# MC3_MMR_ICONT register map
Vendor: Texas Instruments
Peripheral module from a debugger description file (folder DRA75x_DRA74x).
Registers are 32-bit, read-write, reset 0x0 unless marked. A register's access mark holds for its fields unless they carry their own. Offsets are as the file gives them; lines under a group give offsets from that group; [hi:lo] are bit positions; {n}, {i} and the like mark numbered series; 'fields as' and 'values as' point back to an identical list; <NAME> marks a mode.

## MC3_MMR_ICONT
0x00 MC_PID ro reset not defined — PID register
  [31:0] PID — PID of the MC3 module
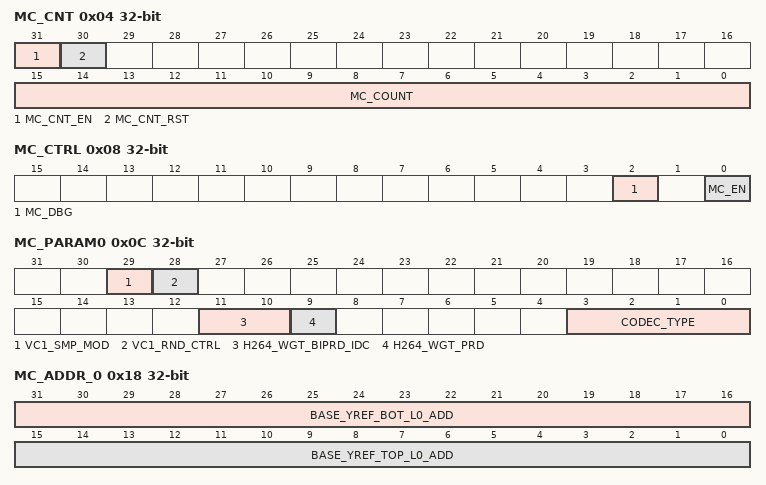
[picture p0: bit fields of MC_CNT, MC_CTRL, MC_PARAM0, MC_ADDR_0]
0x04 MC_CNT access per field — Benchmark counter register
  [31] MC_CNT_EN rw — Counter enable (MC_CNT_EN) 0: The benchmark counter is disabled. 1: The benchmark counter is enabled.
  [30] MC_CNT_RST wo — Counter reset (MC_CNT_RST) Writing 0 results in no effect. Writing 1 results in clearing the benchmark counter to 0. Always read as 0.
  [15:0] MC_COUNT ro — Counter value (MC_COUNT). Indicates current value of the benchmark counter. When MC_CNT_EN is 1 and IP is busy (en = 1), the benchmark counter counts up based on clk_mc. Writing has no effect.
0x08 MC_CTRL access per field — Control register
  [2] MC_DBG rw — H.264 MBAFF debug mode bit (MC_DBG). This bit is used for H.264 MBAFF mode only. For the other codecs, this bit must be 0. 0: Normal mode 1: Debug mode(1MB prediction/step)
  [0] MC_EN rw — Module start and status (MC_EN). Writing 1 starts a set of commands, and writing 0 is ignored. Writing to this register is forbidden while MC_EN = 1. 0: Idle 1: Busy
0x0C MC_PARAM0 access per field — Motion compression parameter register
  [29] VC1_SMP_MOD rw — VC-1 sample mode 0: Bilinear Interpolation 1: Bicubic Interpolation
  [28] VC1_RND_CTRL rw — VC-1 round control bit
  [11:10] H264_WGT_BIPRD_IDC rw — H.264 weighted_bipred_idc
  [9] H264_WGT_PRD rw — H.264 weighted_pred_flag
  [3:0] CODEC_TYPE rw — Codec_type select 0: H.264 2: VC-1 4: MPEG-4 5: MPEG-2 6: AVS-1.0 8: RealVideo-8/9/10 9: On2 VP6 10: On2 VP7
0x10 MC_PARAM1 ro — Motion compression parameter register
0x18 MC_ADDR_0 — Base address of reference data Luma L0
  [31:16] BASE_YREF_BOT_L0_ADD — Base address of reference data Y L0 bottom (BASE_YREF_BOT_L0_ADD) (Reference for bottom field)
  [15:0] BASE_YREF_TOP_L0_ADD — Base address of reference data Y L0 top (BASE_YREF_TOP_L0_ADD) (Reference for progressive/top field)
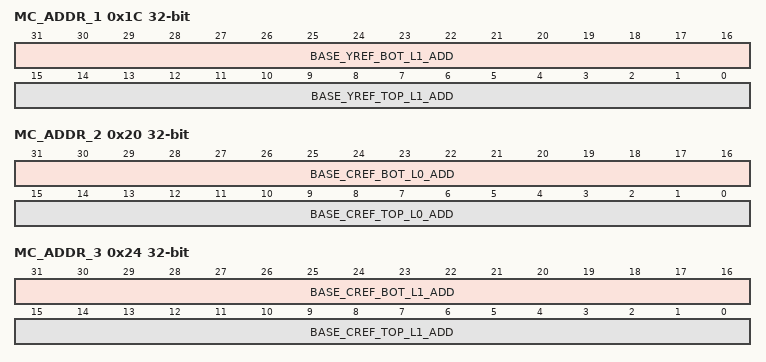
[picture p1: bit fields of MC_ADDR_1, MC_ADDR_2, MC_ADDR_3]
0x1C MC_ADDR_1 — Base address of reference data Luma L1
  [31:16] BASE_YREF_BOT_L1_ADD — Base address of reference data Y L1 bottom (BASE_YREF_BOT_L1_ADD) (Reference for bottom field)
  [15:0] BASE_YREF_TOP_L1_ADD — Base address of reference data Y L1 top (BASE_YREF_TOP_L1_ADD) (Reference for progressive/top field)
0x20 MC_ADDR_2 — Base address of reference data chroma L0
  [31:16] BASE_CREF_BOT_L0_ADD — Base address of reference data C L0 bottom (BASE_CREF_BOT_L0_ADD) (Reference for bottom field)
  [15:0] BASE_CREF_TOP_L0_ADD — Base address of reference data C L0 top (BASE_CREF_TOP_L0_ADD) (Reference for progressive/top field)
0x24 MC_ADDR_3
  [31:16] BASE_CREF_BOT_L1_ADD — Base address of reference data C L1 bottom (BASE_CREF_BOT_L1_ADD) (Reference for bottom field)
  [15:0] BASE_CREF_TOP_L1_ADD — Base address of reference data C L1 top (BASE_CREF_TOP_L1_ADD) (Reference for progressive/top field)
